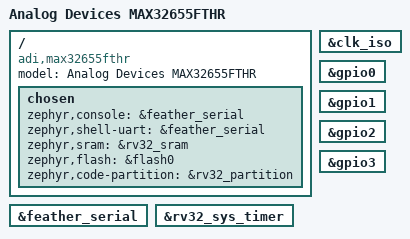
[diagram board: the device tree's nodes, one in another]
/*
 * Copyright (c) 2026 Analog Devices, Inc.
 *
 * SPDX-License-Identifier: Apache-2.0
 */

/dts-v1/;

#include <adi/max32/max32655-rv32.dtsi>
#include "max32655fthr.dtsi"

/ {
	model = "Analog Devices MAX32655FTHR";
	compatible = "adi,max32655fthr";

	chosen {
		zephyr,console = &feather_serial;
		zephyr,shell-uart = &feather_serial;
		zephyr,sram = &rv32_sram;
		zephyr,flash = &flash0;
		zephyr,code-partition = &rv32_partition;
	};
};

&feather_serial {
	status = "okay";
};

&rv32_sys_timer {
	status = "okay";
};

&clk_iso {
	status = "okay";
};

&gpio0 {
	status = "okay";
};

&gpio1 {
	status = "okay";
};

&gpio2 {
	status = "okay";
};

&gpio3 {
	status = "okay";
};
